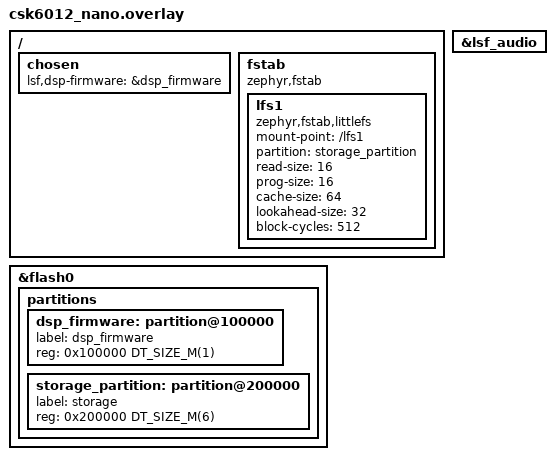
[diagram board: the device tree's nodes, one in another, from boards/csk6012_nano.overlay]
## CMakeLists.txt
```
# Copyright (c) 2023 LISTENAI
# SPDX-License-Identifier: Apache-2.0

cmake_minimum_required(VERSION 3.20.0)

find_package(Zephyr REQUIRED HINTS $ENV{ZEPHYR_BASE})
project(audio_recorder)

target_sources(app PRIVATE src/main.c)
```

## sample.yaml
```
sample:
  name: audio_recorder
tests:
  sample.audio_recorder:
    tags: audio
```

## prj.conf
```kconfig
CONFIG_GPIO=y

CONFIG_HEAP_MEM_POOL_SIZE=204800

CONFIG_CSK_HEAP=y
CONFIG_CSK_HEAP_MEM_POOL_SIZE=40960

CONFIG_CSK6_FLASH_STALL_SECOND_CORE=n

CONFIG_FLASH=y
CONFIG_FLASH_MAP=y
CONFIG_FLASH_PAGE_LAYOUT=y

CONFIG_FILE_SYSTEM=y
CONFIG_FILE_SYSTEM_LITTLEFS=y
```

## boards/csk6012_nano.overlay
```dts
/*
 * Copyright(c) 2023 LISTENAI
 * SPDX-License-Identifier: Apache-2.0
 */

#include <lsf/lsf.dtsi>

/delete-node/ &storage_partition;

/ {
	chosen {
		lsf,dsp-firmware = &dsp_firmware;
	};

	fstab {
		compatible = "zephyr,fstab";
		lfs1: lfs1 {
			compatible = "zephyr,fstab,littlefs";
			mount-point = "/lfs1";
			partition = <&storage_partition>;
			// automount;
			// no-format;
			read-size = <16>;
			prog-size = <16>;
			cache-size = <64>;
			lookahead-size = <32>;
			block-cycles = <512>;
		};
	};
};

&flash0 {
	partitions {
		dsp_firmware: partition@100000 {
			label = "dsp_firmware";
			reg = <0x100000 DT_SIZE_M(1)>;
		};

		storage_partition: partition@200000 {
			label = "storage";
			reg = <0x200000 DT_SIZE_M(6)>;
		};
	};
};

&lsf_audio {
	status = "okay";
};
```

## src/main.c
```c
/*
 * Copyright(c) 2023 LISTENAI
 * SPDX-License-Identifier: Apache-2.0
 */

#include <assert.h>

#include <zephyr/kernel.h>
#include <zephyr/device.h>
#include <zephyr/drivers/gpio.h>

#include "AudioSystem.h"
#include "AudioTrack.h"
#include "AudioRecord.h"

#define SAMPLE_RATE (16000)
#define CHANNEL_CNT (1)

#define RECORD_SECS       (5)
#define RECORD_SAMPLE_CNT (SAMPLE_RATE * RECORD_SECS)

static const struct gpio_dt_spec btn = GPIO_DT_SPEC_GET(DT_ALIAS(sw0), gpios);
static const struct gpio_dt_spec led = GPIO_DT_SPEC_GET(DT_ALIAS(led0), gpios);

static struct gpio_callback btn_cb_data;

static AudioRecord s_record_obj;
static AudioTrack s_track_obj;

static struct k_sem s_sem_record;
static volatile bool s_busy;

__attribute__((section(".psram_section"))) static uint8_t
	recording[sizeof(uint16_t) * RECORD_SAMPLE_CNT * CHANNEL_CNT];

static void button_pressed(const struct device *dev, struct gpio_callback *cb, uint32_t pins)
{
	printk("Button pressed at %" PRIu32 "\n", k_cycle_get_32());

	if (!s_busy) {
		k_sem_give(&s_sem_record);
	}
}

void main(void)
{
	int ret;

	printk("Hello World! %s\n", CONFIG_BOARD);

	k_sem_init(&s_sem_record, 0, 1);

	/* 初始化 GPIO */
	ret = gpio_pin_configure_dt(&btn, GPIO_INPUT);
	assert(0 == ret);

	ret = gpio_pin_configure_dt(&led, GPIO_OUTPUT_INACTIVE);
	assert(0 == ret);

	/* 初始化音频组件 */
	String8 param;
	String8_ctor_char(&param, "ADC_PDM_GAIN_A_LEFT=6;"
				  "ADC_PDM_GAIN_D_LEFT=20;"
				  "ADC_PDM_GAIN_A_RIGHT=6;"
				  "ADC_PDM_GAIN_D_RIGHT=20");
	ret = AudioSystem_setParameters(0, &param);
	String8_dtor(&param);
	assert(0 == ret);

	AudioRecord *record = &s_record_obj;
	ret = AudioRecord_ctor(record, 0, SAMPLE_RATE, PCM_16_BIT, CHANNEL_IN_LEFT, 0, NULL);
	assert(0 == ret);

	AudioTrack *track = &s_track_obj;
	ret = AudioTrack_ctor(track, SAMPLE_RATE, PCM_16_BIT, CHANNEL_OUT_MONO, 0, NULL);
	assert(0 == ret);

	ret = gpio_pin_interrupt_configure_dt(&btn, GPIO_INT_EDGE_TO_ACTIVE);
	assert(0 == ret);

	gpio_init_callback(&btn_cb_data, button_pressed, BIT(btn.pin));
	gpio_add_callback(btn.port, &btn_cb_data);

	ssize_t size;
	while (1) {
		printk("Press the button\n");

		/* 循环等待按键按下 */
		k_sem_take(&s_sem_record, K_FOREVER);
		s_busy = true;

		gpio_pin_set_dt(&led, 1);

		printk("Records 5 seconds...\n");

		AudioRecord_start(record);
		size = AudioRecord_read(record, recording,
					sizeof(int16_t) * RECORD_SAMPLE_CNT * CHANNEL_CNT);
		AudioRecord_stop(record);
		assert(size > 0);

		gpio_pin_set_dt(&led, 0);

		printk("Plays 5 seconds...\n");

		AudioTrack_start(track);
		size = AudioTrack_write(track, recording, size);
		assert(size > 0);
		AudioTrack_stop(track);

		s_busy = false;
	}
}
```
